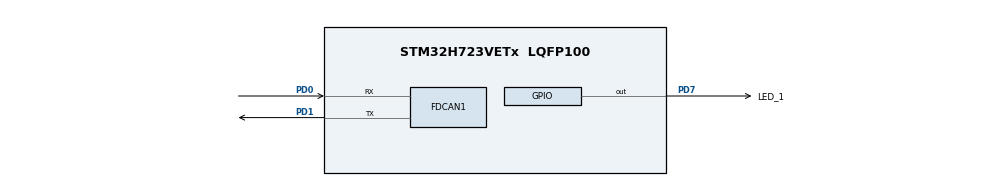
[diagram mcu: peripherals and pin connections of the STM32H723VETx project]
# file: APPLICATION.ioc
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CORTEX_M7.default_mode_Activation=1
FDCAN1.AutoRetransmission=ENABLE
FDCAN1.CalculateBaudRateNominal=1000000
FDCAN1.CalculateTimeBitNominal=1000
FDCAN1.CalculateTimeQuantumNominal=20.833333333333332
FDCAN1.DataPrescaler=1
FDCAN1.DataTimeSeg1=27
FDCAN1.DataTimeSeg2=10
FDCAN1.FrameFormat=FDCAN_FRAME_FD_NO_BRS
FDCAN1.NominalPrescaler=1
FDCAN1.NominalTimeSeg1=27
FDCAN1.NominalTimeSeg2=20
FDCAN1.RxBufferSize=FDCAN_DATA_BYTES_64
FDCAN1.RxFifo0ElmtSize=FDCAN_DATA_BYTES_64
FDCAN1.RxFifo0ElmtsNbr=64
FDCAN1.RxFifo1ElmtSize=FDCAN_DATA_BYTES_64
FDCAN1.TxElmtSize=FDCAN_DATA_BYTES_64
FREERTOS.Tasks01=defaultTask,24,128,StartDefaultTask,Default,NULL,Dynamic,NULL,NULL;Task1,24,128,OTA_Task,As external,NULL,Dynamic,NULL,NULL
Mcu.Family=STM32H7
Mcu.Name=STM32H723VETx
Mcu.Package=LQFP100
NVIC.FDCAN1_IT0_IRQn=true\:5\:0\:false\:false\:true\:true\:true\:true\:true
NVIC.FDCAN1_IT1_IRQn=true\:5\:0\:false\:false\:true\:true\:true\:true\:true
NVIC.PriorityGroup=NVIC_PRIORITYGROUP_4
NVIC.TIM1_UP_IRQn=true\:15\:0\:false\:false\:true\:false\:false\:true\:true
NVIC.TimeBase=TIM1_UP_IRQn
NVIC.TimeBaseIP=TIM1
PD0.Mode=FDCAN_Activate
PD0.Signal=FDCAN1_RX
PD1.Mode=FDCAN_Activate
PD1.Signal=FDCAN1_TX
PD7.GPIO_Label=LED_1
PD7.Signal=GPIO_Output
PH0-OSC_IN.Mode=HSE-External-Oscillator
PH0-OSC_IN.Signal=RCC_OSC_IN
PH1-OSC_OUT.Mode=HSE-External-Oscillator
PH1-OSC_OUT.Signal=RCC_OSC_OUT
ProjectManager.HeapSize=0x200
ProjectManager.StackSize=0x400
ProjectManager.TargetToolchain=STM32CubeIDE
RCC.ADCFreq_Value=129000000
RCC.APB1Freq_Value=64000000
RCC.APB2Freq_Value=64000000
RCC.APB3Freq_Value=64000000
RCC.APB4Freq_Value=64000000
RCC.CortexFreq_Value=64000000
RCC.DIVM1=4
RCC.DIVN1=12
RCC.DIVQ1=4
RCC.HCLKFreq_Value=64000000
RCC.PLL1_VCI_Range=RCC_PLL1VCIRANGE_3
RCC.PLLFRACN=0
RCC.SYSCLKFreq_VALUE=64000000
RCC.USBFreq_Value=48000000
VP_FREERTOS_VS_CMSIS_V2.Mode=CMSIS_V2
VP_MEMORYMAP_VS_MEMORYMAP.Mode=CurAppReg
VP_SYS_VS_tim1.Mode=TIM1
board=custom

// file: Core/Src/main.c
/* USER CODE BEGIN Header */
/**
 ******************************************************************************
 * @file           : main.c
 * @brief          : Main program body
 ******************************************************************************
 * @attention
 *
 * Copyright (c) 2025 STMicroelectronics.
 * All rights reserved.
 *
 * This software is licensed under terms that can be found in the LICENSE file
 * in the root directory of this software component.
 * If no LICENSE file comes with this software, it is provided AS-IS.
 *
 ******************************************************************************
 */
/* USER CODE END Header */
#include "main.h"
#include "cmsis_os.h"
#include "fdcan.h"
#include "memorymap.h"
#include "gpio.h"

void SystemClock_Config(void);
static void MPU_Config(void);
void MX_FREERTOS_Init(void);

int main(void)
{

  /* MPU Configuration--------------------------------------------------------*/
  MPU_Config();

  /* MCU Configuration--------------------------------------------------------*/

  /* Reset of all peripherals, Initializes the Flash interface and the Systick. */
  HAL_Init();

  /* Configure the system clock */
  SystemClock_Config();

  /* Initialize all configured peripherals */
  MX_GPIO_Init();
  MX_FDCAN1_Init();

  /* Init scheduler */
  osKernelInitialize();

  /* Call init function for freertos objects (in cmsis_os2.c) */
  MX_FREERTOS_Init();

  /* Start scheduler */
  osKernelStart();

  /* We should never get here as control is now taken by the scheduler */

  /* Infinite loop */
	while (1)
	{

	}
}

void SystemClock_Config(void)
{
  RCC_OscInitTypeDef RCC_OscInitStruct = {0};
  RCC_ClkInitTypeDef RCC_ClkInitStruct = {0};

  /** Supply configuration update enable
  */
  HAL_PWREx_ConfigSupply(PWR_LDO_SUPPLY);

  /** Configure the main internal regulator output voltage
  */
  __HAL_PWR_VOLTAGESCALING_CONFIG(PWR_REGULATOR_VOLTAGE_SCALE3);

  while(!__HAL_PWR_GET_FLAG(PWR_FLAG_VOSRDY)) {}

  /** Initializes the RCC Oscillators according to the specified parameters
  * in the RCC_OscInitTypeDef structure.
  */
  RCC_OscInitStruct.OscillatorType = RCC_OSCILLATORTYPE_HSI;
  RCC_OscInitStruct.HSIState = RCC_HSI_DIV1;
  RCC_OscInitStruct.HSICalibrationValue = 64;
  RCC_OscInitStruct.PLL.PLLState = RCC_PLL_ON;
  RCC_OscInitStruct.PLL.PLLSource = RCC_PLLSOURCE_HSI;
  RCC_OscInitStruct.PLL.PLLM = 4;
  RCC_OscInitStruct.PLL.PLLN = 12;
  RCC_OscInitStruct.PLL.PLLP = 2;
  RCC_OscInitStruct.PLL.PLLQ = 4;
  RCC_OscInitStruct.PLL.PLLR = 2;
  RCC_OscInitStruct.PLL.PLLRGE = RCC_PLL1VCIRANGE_3;
  RCC_OscInitStruct.PLL.PLLVCOSEL = RCC_PLL1VCOWIDE;
  RCC_OscInitStruct.PLL.PLLFRACN = 0;
  if (HAL_RCC_OscConfig(&RCC_OscInitStruct) != HAL_OK)
  {
    Error_Handler();
  }

  /** Initializes the CPU, AHB and APB buses clocks
  */
  RCC_ClkInitStruct.ClockType = RCC_CLOCKTYPE_HCLK|RCC_CLOCKTYPE_SYSCLK
                              |RCC_CLOCKTYPE_PCLK1|RCC_CLOCKTYPE_PCLK2
                              |RCC_CLOCKTYPE_D3PCLK1|RCC_CLOCKTYPE_D1PCLK1;
  RCC_ClkInitStruct.SYSCLKSource = RCC_SYSCLKSOURCE_HSI;
  RCC_ClkInitStruct.SYSCLKDivider = RCC_SYSCLK_DIV1;
  RCC_ClkInitStruct.AHBCLKDivider = RCC_HCLK_DIV1;
  RCC_ClkInitStruct.APB3CLKDivider = RCC_APB3_DIV1;
  RCC_ClkInitStruct.APB1CLKDivider = RCC_APB1_DIV1;
  RCC_ClkInitStruct.APB2CLKDivider = RCC_APB2_DIV1;
  RCC_ClkInitStruct.APB4CLKDivider = RCC_APB4_DIV1;

  if (HAL_RCC_ClockConfig(&RCC_ClkInitStruct, FLASH_LATENCY_1) != HAL_OK)
  {
    Error_Handler();
  }
}

 /* MPU Configuration */

void MPU_Config(void)
{
  MPU_Region_InitTypeDef MPU_InitStruct = {0};

  /* Disables the MPU */
  HAL_MPU_Disable();

  /** Initializes and configures the Region and the memory to be protected
  */
  MPU_InitStruct.Enable = MPU_REGION_ENABLE;
  MPU_InitStruct.Number = MPU_REGION_NUMBER0;
  MPU_InitStruct.BaseAddress = 0x0;
  MPU_InitStruct.Size = MPU_REGION_SIZE_4GB;
  MPU_InitStruct.SubRegionDisable = 0x87;
  MPU_InitStruct.TypeExtField = MPU_TEX_LEVEL0;
  MPU_InitStruct.AccessPermission = MPU_REGION_NO_ACCESS;
  MPU_InitStruct.DisableExec = MPU_INSTRUCTION_ACCESS_DISABLE;
  MPU_InitStruct.IsShareable = MPU_ACCESS_SHAREABLE;
  MPU_InitStruct.IsCacheable = MPU_ACCESS_NOT_CACHEABLE;
  MPU_InitStruct.IsBufferable = MPU_ACCESS_NOT_BUFFERABLE;

  HAL_MPU_ConfigRegion(&MPU_InitStruct);
  /* Enables the MPU */
  HAL_MPU_Enable(MPU_PRIVILEGED_DEFAULT);

}

void HAL_TIM_PeriodElapsedCallback(TIM_HandleTypeDef *htim)
{
  if (htim->Instance == TIM1) {
    HAL_IncTick();
  }
}

void Error_Handler(void)
{
	__disable_irq();
	while (1)
	{
	}
}

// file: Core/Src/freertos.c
/* USER CODE BEGIN Header */
/**
  ******************************************************************************
  * File Name          : freertos.c
  * Description        : Code for freertos applications
  ******************************************************************************
  * @attention
  *
  * Copyright (c) 2025 STMicroelectronics.
  * All rights reserved.
  *
  * This software is licensed under terms that can be found in the LICENSE file
  * in the root directory of this software component.
  * If no LICENSE file comes with this software, it is provided AS-IS.
  *
  ******************************************************************************
  */
/* USER CODE END Header */

#include "FreeRTOS.h"
#include "task.h"
#include "main.h"
#include "cmsis_os.h"

/* Definitions for defaultTask */
osThreadId_t defaultTaskHandle;
const osThreadAttr_t defaultTask_attributes = {
  .name = "defaultTask",
  .stack_size = 128 * 4,
  .priority = (osPriority_t) osPriorityNormal,
};
/* Definitions for Task1 */
osThreadId_t Task1Handle;
const osThreadAttr_t Task1_attributes = {
  .name = "Task1",
  .stack_size = 128 * 4,
  .priority = (osPriority_t) osPriorityNormal,
};

void StartDefaultTask(void *argument);
extern void OTA_Task(void *argument);

void MX_FREERTOS_Init(void); /* (MISRA C 2004 rule 8.1) */

void MX_FREERTOS_Init(void) {

  /* Create the thread(s) */
  /* creation of defaultTask */
  defaultTaskHandle = osThreadNew(StartDefaultTask, NULL, &defaultTask_attributes);

  /* creation of Task1 */
  Task1Handle = osThreadNew(OTA_Task, NULL, &Task1_attributes);

}

void StartDefaultTask(void *argument)
{
  for(;;)
  {
    osDelay(1);
  }
}

/* USER CODE BEGIN Application */
void OTA_Task(void *argument)
{
  /* USER CODE BEGIN StartDefaultTask */
  /* Infinite loop */
  for(;;)
  {
	  fun();
    osDelay(100);
  }
  /* USER CODE END StartDefaultTask */
}
/* USER CODE END Application */
